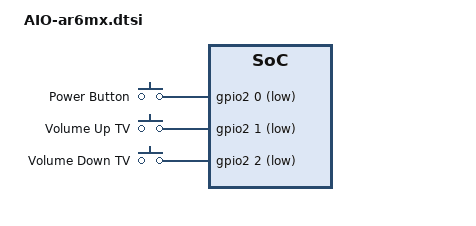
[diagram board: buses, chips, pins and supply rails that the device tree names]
/ {
        gpio-keys {
                compatible = "gpio-keys";

                power-button {
                        label = "Power Button";
                        gpios = <&gpio2 0 GPIO_ACTIVE_LOW>;
                        linux,code = <116>; /* KEY_POWER */
                        gpio-key,wakeup;
                        linux,input-type=<1>; /* EV_KEY, default, but included for completeness */
                };  

                volume-up-tv {
                        label = "Volume Up TV";
                        gpios = <&gpio2 1 GPIO_ACTIVE_LOW>;
                        linux,code = <115>; /* KEY_VOLUMEUP */
                        linux,input-type=<0>; /* EV_SYN */
                };  


                volume-down-tv {
                        label = "Volume Down TV";
                        gpios = <&gpio2 2 GPIO_ACTIVE_LOW>;
                        linux,code = <114>; /* KEY_VOLUMEDOWN */
                        linux,input-type=<0>; /* EV_SYN */
                };  

        };
};
